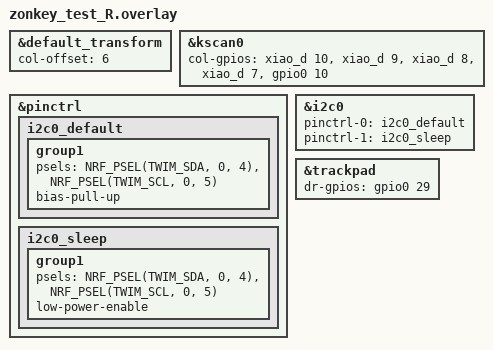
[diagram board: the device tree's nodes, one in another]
#include "zonkey_test.dtsi"

&default_transform {
    col-offset = <6>;
};

&kscan0 {
    col-gpios
        = <&xiao_d 10 GPIO_ACTIVE_HIGH>
        , <&xiao_d 9 GPIO_ACTIVE_HIGH> 
        , <&xiao_d 8 GPIO_ACTIVE_HIGH> 
        , <&xiao_d 7 GPIO_ACTIVE_HIGH> 
        , <&gpio0 10 GPIO_ACTIVE_HIGH>
        ;
};

&pinctrl {
    i2c0_default: i2c0_default {
        group1 {
            psels = <NRF_PSEL(TWIM_SDA, 0, 4)>,
                    <NRF_PSEL(TWIM_SCL, 0, 5)>;
            bias-pull-up;
        };
    };

    i2c0_sleep: i2c0_sleep {
        group1 {
            psels = <NRF_PSEL(TWIM_SDA, 0, 4)>,
                    <NRF_PSEL(TWIM_SCL, 0, 5)>;
            low-power-enable;
        };
    };
};

&i2c0 {
    status = "okay";
    pinctrl-0 = <&i2c0_default>;
    pinctrl-1 = <&i2c0_sleep>;
    pinctrl-names = "default", "sleep";
};

/* 参照は i2c0 のブロックの外に記述します */
&trackpad {
    dr-gpios = <&gpio0 29 (GPIO_ACTIVE_HIGH)>; 
};
